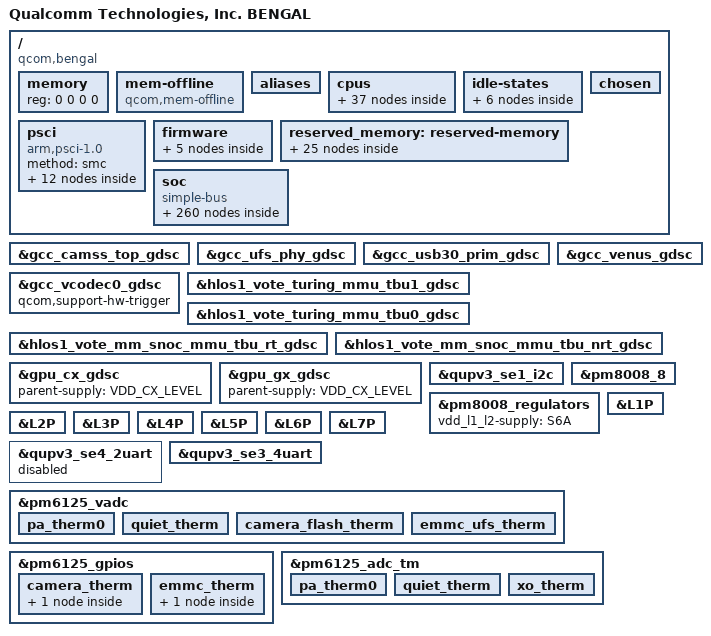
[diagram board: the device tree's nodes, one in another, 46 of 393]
#include <dt-bindings/interrupt-controller/arm-gic.h>
#include <dt-bindings/clock/qcom,rpmcc.h>
#include <dt-bindings/clock/qcom,sm6115-dispcc.h>
#include <dt-bindings/clock/qcom,gcc-sm6115.h>
#include <dt-bindings/clock/qcom,sm6115-gpucc.h>
#include <dt-bindings/spmi/spmi.h>
#include <dt-bindings/interconnect/qcom,bengal.h>
#include <dt-bindings/regulator/qcom,rpmh-regulator-levels.h>

/ {
	model = "Qualcomm Technologies, Inc. BENGAL";
	compatible = "qcom,bengal";
	qcom,msm-id = <417 0x10000>, <444 0x10000>;
	interrupt-parent = <&intc>;

	#address-cells = <2>;
	#size-cells = <2>;
	memory { device_type = "memory"; reg = <0 0 0 0>; };

	mem-offline {
		compatible = "qcom,mem-offline";
		offline-sizes = <0x1 0x40000000 0x0 0x40000000>,
				<0x1 0xc0000000 0x0 0x80000000>,
				<0x2 0xc0000000 0x1 0x40000000>;
		granule = <512>;
	};

	aliases: aliases {
		mmc0 = &sdhc_1; /* SDC1 eMMC slot */
		mmc1 = &sdhc_2; /* SDC2 SD Card slot */
		ufshc1 = &ufshc_mem; /* Embedded UFS slot */
		serial0 = &qupv3_se4_2uart;
		hsuart0 = &qupv3_se3_4uart;
	};

	cpus {
		#address-cells = <2>;
		#size-cells = <0>;

		CPU0: cpu@0 {
			device_type = "cpu";
			compatible = "arm,armv8";
			reg = <0x0 0x0>;
			capacity-dmips-mhz = <1024>;
			dynamic-power-coefficient = <100>;
			cpu-idle-states = <&SILVER_OFF>;
			power-domains = <&CPU_PD0>;
			power-domain-names = "psci";
			enable-method = "psci";
			next-level-cache = <&L2_0>;
			qcom,freq-domain = <&cpufreq_hw 0 7>;
			qcom,lmh-dcvs = <&lmh_dcvs0>;
			#cooling-cells = <2>;
			L2_0: l2-cache {
				compatible = "arm,arch-cache";
				cache-level = <2>;
			};

			L1_I_0: l1-icache {
				compatible = "arm,arch-cache";
			};

			L1_D_0: l1-dcache {
				compatible = "arm,arch-cache";
			};
		};

		CPU1: cpu@1 {
			device_type = "cpu";
			compatible = "arm,armv8";
			reg = <0x0 0x1>;
			capacity-dmips-mhz = <1024>;
			dynamic-power-coefficient = <100>;
			cpu-idle-states = <&SILVER_OFF>;
			power-domains = <&CPU_PD0>;
			power-domain-names = "psci";
			enable-method = "psci";
			next-level-cache = <&L2_0>;
			qcom,freq-domain = <&cpufreq_hw 0 7>;
			qcom,lmh-dcvs = <&lmh_dcvs0>;
			#cooling-cells = <2>;

			L1_I_1: l1-icache {
				compatible = "arm,arch-cache";
			};

			L1_D_1: l1-dcache {
				compatible = "arm,arch-cache";
			};
		};

		CPU2: cpu@2 {
			device_type = "cpu";
			compatible = "arm,armv8";
			reg = <0x0 0x2>;
			capacity-dmips-mhz = <1024>;
			dynamic-power-coefficient = <100>;
			cpu-idle-states = <&SILVER_OFF>;
			power-domains = <&CPU_PD0>;
			power-domain-names = "psci";
			enable-method = "psci";
			next-level-cache = <&L2_0>;
			qcom,freq-domain = <&cpufreq_hw 0 7>;
			qcom,lmh-dcvs = <&lmh_dcvs0>;
			#cooling-cells = <2>;

			L1_I_2: l1-icache {
				compatible = "arm,arch-cache";
			};

			L1_D_2: l1-dcache {
				compatible = "arm,arch-cache";
			};
		};

		CPU3: cpu@3 {
			device_type = "cpu";
			compatible = "arm,armv8";
			reg = <0x0 0x3>;
			capacity-dmips-mhz = <1024>;
			dynamic-power-coefficient = <100>;
			cpu-idle-states = <&SILVER_OFF>;
			power-domains = <&CPU_PD0>;
			power-domain-names = "psci";
			enable-method = "psci";
			next-level-cache = <&L2_0>;
			qcom,freq-domain = <&cpufreq_hw 0 7>;
			qcom,lmh-dcvs = <&lmh_dcvs0>;
			#cooling-cells = <2>;

			L1_I_3: l1-icache {
				compatible = "arm,arch-cache";
			};

			L1_D_3: l1-dcache {
				compatible = "arm,arch-cache";
			};
		};

		CPU4: cpu@100 {
			device_type = "cpu";
			compatible = "arm,armv8";
			reg = <0x0 0x100>;
			cpu-idle-states = <&GOLD_OFF>;
			power-domains = <&CPU_PD4>;
			power-domain-names = "psci";
			enable-method = "psci";
			capacity-dmips-mhz = <1638>;
			dynamic-power-coefficient = <282>;
			next-level-cache = <&L2_1>;
			qcom,freq-domain = <&cpufreq_hw 1 7>;
			qcom,lmh-dcvs = <&lmh_dcvs1>;
			#cooling-cells = <2>;
			L2_1: l2-cache {
				compatible = "arm,arch-cache";
				cache-level = <2>;
			};

			L1_I_100: l1-icache {
				compatible = "arm,arch-cache";
			};

			L1_D_100: l1-dcache {
				compatible = "arm,arch-cache";
			};
		};

		CPU5: cpu@101 {
			device_type = "cpu";
			compatible = "arm,armv8";
			reg = <0x0 0x101>;
			capacity-dmips-mhz = <1638>;
			dynamic-power-coefficient = <282>;
			cpu-idle-states = <&GOLD_OFF>;
			power-domains = <&CPU_PD4>;
			power-domain-names = "psci";
			enable-method = "psci";
			next-level-cache = <&L2_1>;
			qcom,freq-domain = <&cpufreq_hw 1 7>;
			qcom,lmh-dcvs = <&lmh_dcvs1>;
			#cooling-cells = <2>;

			L1_I_101: l1-icache {
				compatible = "arm,arch-cache";
			};

			L1_D_101: l1-dcache {
				compatible = "arm,arch-cache";
			};
		};

		CPU6: cpu@102 {
			device_type = "cpu";
			compatible = "arm,armv8";
			reg = <0x0 0x102>;
			capacity-dmips-mhz = <1638>;
			dynamic-power-coefficient = <282>;
			cpu-idle-states = <&GOLD_OFF>;
			power-domains = <&CPU_PD4>;
			power-domain-names = "psci";
			enable-method = "psci";
			next-level-cache = <&L2_1>;
			qcom,freq-domain = <&cpufreq_hw 1 7>;
			qcom,lmh-dcvs = <&lmh_dcvs1>;
			#cooling-cells = <2>;

			L1_I_102: l1-icache {
				compatible = "arm,arch-cache";
			};

			L1_D_102: l1-dcache {
				compatible = "arm,arch-cache";
			};
		};

		CPU7: cpu@103 {
			device_type = "cpu";
			compatible = "arm,armv8";
			reg = <0x0 0x103>;
			capacity-dmips-mhz = <1638>;
			dynamic-power-coefficient = <282>;
			cpu-idle-states = <&GOLD_OFF>;
			power-domains = <&CPU_PD4>;
			power-domain-names = "psci";
			enable-method = "psci";
			next-level-cache = <&L2_1>;
			qcom,freq-domain = <&cpufreq_hw 1 7>;
			qcom,lmh-dcvs = <&lmh_dcvs1>;
			#cooling-cells = <2>;

			L1_I_103: l1-icache {
				compatible = "arm,arch-cache";
			};

			L1_D_103: l1-dcache {
				compatible = "arm,arch-cache";
			};
		};

		cpu-map {
			cluster0 {
				core0 {
					cpu = <&CPU0>;
				};

				core1 {
					cpu = <&CPU1>;
				};

				core2 {
					cpu = <&CPU2>;
				};

				core3 {
					cpu = <&CPU3>;
				};
			};

			cluster1 {
				core0 {
					cpu = <&CPU4>;
				};

				core1 {
					cpu = <&CPU5>;
				};

				core2 {
					cpu = <&CPU6>;
				};

				core3 {
					cpu = <&CPU7>;
				};
			};
		};
	};

	idle-states {
		SILVER_OFF: silver-c3 {  /* C3 */
			compatible = "arm,idle-state";
			idle-state-name = "pc";
			entry-latency-us = <297>;
			exit-latency-us = <324>;
			min-residency-us = <1110>;
			arm,psci-suspend-param = <0x40000003>;
			local-timer-stop;
		};

		GOLD_OFF: gold-c3 {  /* C3 */
			compatible = "arm,idle-state";
			idle-state-name = "pc";
			entry-latency-us = <290>;
			exit-latency-us = <376>;
			min-residency-us = <1182>;
			arm,psci-suspend-param = <0x40000003>;
			local-timer-stop;
		};

		SILVER_CLUSTER_D3: silver-cluster-d3 { /* D3 */
			compatible = "domain-idle-state";
			idle-state-name = "pwr-l2-pc";
			entry-latency-us = <640>;
			exit-latency-us = <1664>;
			min-residency-us = <8094>;
			arm,psci-suspend-param = <0x41000043>;
		};

		GOLD_CLUSTER_D3: gold-cluster-d3 { /* D3 */
			compatible = "domain-idle-state";
			idle-state-name = "perf-l2-pc";
			entry-latency-us = <800>;
			exit-latency-us = <2118>;
			min-residency-us = <7376>;
			arm,psci-suspend-param = <0x41000043>;
		};

		APSS_WFI: cluster-e1 { /* E1 */
			compatible = "domain-idle-state";
			idle-state-name = "cci-ret";
			entry-latency-us = <108>;
			exit-latency-us = <450>;
			min-residency-us = <153>;
			arm,psci-suspend-param = <0x42000043>;
		};

		APSS_OFF: cluster-e3 { /* E3 */
			compatible = "domain-idle-state";
			idle-state-name = "cci-pc";
			entry-latency-us = <10831>;
			exit-latency-us = <4506>;
			min-residency-us = <15338>;
			arm,psci-suspend-param = <0x42000343>;
		};
	};

	psci {
		compatible = "arm,psci-1.0";
		method = "smc";

		CPU_PD0: cpu-pd0 {
			#power-domain-cells = <0>;
			power-domains = <&CLUSTER_PD0>;
		};

		CPU_PD1: cpu-pd1 {
			#power-domain-cells = <0>;
			power-domains = <&CLUSTER_PD0>;
		};

		CPU_PD2: cpu-pd2 {
			#power-domain-cells = <0>;
			power-domains = <&CLUSTER_PD0>;
		};

		CPU_PD3: cpu-pd3 {
			#power-domain-cells = <0>;
			power-domains = <&CLUSTER_PD0>;
		};

		CPU_PD4: cpu-pd4 {
			#power-domain-cells = <0>;
			power-domains = <&CLUSTER_PD1>;
		};

		CPU_PD5: cpu-pd5 {
			#power-domain-cells = <0>;
			power-domains = <&CLUSTER_PD1>;
		};

		CPU_PD6: cpu-pd6 {
			#power-domain-cells = <0>;
			power-domains = <&CLUSTER_PD1>;
		};

		CPU_PD7: cpu-pd7 {
			#power-domain-cells = <0>;
			power-domains = <&CLUSTER_PD1>;
		};

		CLUSTER_PD0: cluster-pd0 {
			#power-domain-cells = <0>;
			power-domains = <&CLUSTER_PD2>;
			domain-idle-states = <&SILVER_CLUSTER_D3>;
		};

		CLUSTER_PD1: cluster-pd1 {
			#power-domain-cells = <0>;
			power-domains = <&CLUSTER_PD2>;
			domain-idle-states = <&GOLD_CLUSTER_D3>;
		};

		CLUSTER_PD2: cluster-pd2 {
			#power-domain-cells = <0>;
			power-domains = <&CLUSTER_PD3>;
			domain-idle-states = <&APSS_WFI>;
		};

		CLUSTER_PD3: cluster-pd3 {
			#power-domain-cells = <0>;
			domain-idle-states = <&APSS_OFF>;
		};
	};

	firmware: firmware {
		qcom_scm {
			compatible = "qcom,scm";
			qcom,dload-mode = <&tcsr 0x13000>;
		};

		android {
			compatible = "android,firmware";
			vbmeta {
				compatible="android,vbmeta";
				parts = "vbmeta,boot,system,vendor,dtbo,recovery";
			};

			fstab {
				compatible = "android,fstab";
				vendor {
					compatible = "android,vendor";
					dev = "/dev/block/platform/soc/4744000.sdhci/by-name/vendor";
					type = "ext4";
					mnt_flags = "ro,barrier=1,discard";
					fsmgr_flags = "wait,slotselect,avb";
					status = "ok";
				};
			};
		};
	};

	reserved_memory: reserved-memory {
		#address-cells = <2>;
		#size-cells = <2>;
		ranges;

		hyp_mem: hyp_region@45700000 {
			no-map;
			reg = <0x0 0x45700000 0x0 0x600000>;
		};

		xbl_aop_mem: xbl_aop_region@45e00000 {
			no-map;
			reg = <0x0 0x45e00000 0x0 0x140000>;
		};

		sec_apps_mem: sec_apps_region@45fff000 {
			no-map;
			reg = <0x0 0x45fff000 0x0 0x1000>;
		};

		smem_mem: smem_region@46000000 {
			no-map;
			reg = <0x0 0x46000000 0x0 0x200000>;
		};

		removed_mem: removed_region@60000000 {
			no-map;
			reg = <0x0 0x60000000 0x0 0x3900000>;
		};

		pil_modem_mem: modem_region@4ab00000 {
			no-map;
			reg = <0x0 0x4ab00000 0x0 0x6900000>;
		};

		wlan_msa_mem: wlan_msa_region@51900000 {
			no-map;
			reg = <0x0 0x51900000 0x0 0x100000>;
		};

		pil_cdsp_mem: cdsp_regions@51a00000 {
			no-map;
			reg = <0x0 0x51a00000 0x0 0x1e00000>;
		};

		pil_adsp_mem: pil_adsp_region@53800000 {
			no-map;
			reg = <0x0 0x53800000 0x0 0x1e00000>;
		};

		pil_ipa_fw_mem: ipa_fw_region@55600000 {
			no-map;
			reg = <0x0 0x55600000 0x0 0x10000>;
		};

		pil_ipa_gsi_mem: ipa_gsi_region@55610000 {
			no-map;
			reg = <0x0 0x55610000 0x0 0x5000>;
		};

		pil_gpu_mem: gpu_region@55615000 {
			no-map;
			reg = <0x0 0x55615000 0x0 0x2000>;
		};

		video_mem: video_region@55617000 {
			no-map;
			reg = <0x0 0x55617000 0x0 0x700000>;
		};

		user_contig_mem: user_contig_region {
			compatible = "shared-dma-pool";
			alloc-ranges = <0x0 0x00000000 0x0 0xffffffff>;
			reusable;
			alignment = <0x0 0x400000>;
			size = <0x0 0x1000000>;
		};

		non_secure_display_memory: non_secure_display_region {
			compatible = "shared-dma-pool";
			reusable;
			alloc-ranges = <0x0 0x00000000 0x0 0xffffffff>;
			size = <0x0 0xa400000>;
			alignment = <0x0 0x400000>;
		};

		qseecom_mem: qseecom_region {
			compatible = "shared-dma-pool";
			alloc-ranges = <0x0 0x00000000 0x0 0xffffffff>;
			reusable;
			alignment = <0x0 0x400000>;
			size = <0x0 0x1400000>;
		};

		qseecom_ta_mem: qseecom_ta_region {
			compatible = "shared-dma-pool";
			alloc-ranges = <0x0 0x00000000 0x0 0xffffffff>;
			reusable;
			alignment = <0x0 0x400000>;
			size = <0x0 0x1000000>;
		};

		cdsp_sec_mem: cdsp_sec_regions@46200000 {
			no-map;
			reg = <0x0 0x46200000 0x0 0x1e00000>;
		};

		secure_display_memory: secure_display_region {
			compatible = "shared-dma-pool";
			alloc-ranges = <0 0x00000000 0 0xffffffff>;
			reusable;
			alignment = <0 0x400000>;
			size = <0 0x5c00000>;
		};

		adsp_mem: adsp_region {
			compatible = "shared-dma-pool";
			alloc-ranges = <0 0x00000000 0 0xffffffff>;
			reusable;
			alignment = <0 0x400000>;
			size = <0 0x800000>;
		};

		dump_mem: mem_dump_region {
			compatible = "shared-dma-pool";
			alloc-ranges = <0x0 0x00000000 0x0 0xffffffff>;
			reusable;
			size = <0 0x800000>;
		};

		ramoops_mem: ramoops_region {
			compatible = "ramoops";
			alloc-ranges = <0x0 0x00000000 0xffffffff 0xffffffff>;
			size = <0x0 0x200000>;
			pmsg-size = <0x200000>;
			mem-type = <2>;
		};

		audio_cma_mem: audio_cma_region {
			compatible = "shared-dma-pool";
			alloc-ranges = <0x0 0x00000000 0x0 0xffffffff>;
			reusable;
			alignment = <0x0 0x400000>;
			size = <0x0 0x1C00000>;
		};

		/* global autoconfigured region for contiguous allocations */
		system_cma: linux,cma {
			compatible = "shared-dma-pool";
			alloc-ranges = <0x0 0x00000000 0x0 0xffffffff>;
			reusable;
			alignment = <0x0 0x400000>;
			size = <0x0 0x2000000>;
			linux,cma-default;
		};

		va_md_mem: va_md_mem_region {
			compatible = "shared-dma-pool";
			alloc-ranges = <0x0 0x00000000 0x0 0xffffffff>;
			reusable;
			size = <0x0 0x1000000>;
		};

	};

	chosen {
		bootargs = "lpm_levels.sleep_disabled=1 console=ttyMSM0,115200n8 msm_rtb.filter=0x237 service_locator.enable=1 swiotlb=2048 loop.max_part=7 cpufreq.default_governor=performance rcupdate.rcu_expedited=1 rcu_nocbs=0-7 kpti=off export_pmu_events movable_node ftrace_dump_on_oops ssbd=force-off disable_dma32=on cgroup.memory=nokmem,nosocket panic=5";
	};

	soc: soc { };
};

&soc {
	#address-cells = <1>;
	#size-cells = <1>;
	ranges = <0 0 0 0xffffffff>;
	compatible = "simple-bus";

	clk_virt: interconnect {
		compatible = "qcom,bengal-clk_virt";
		qcom,keepalive;
		#interconnect-cells = <1>;
		clock-names = "bus", "bus_a";
		clocks = <&rpmcc RPM_SMD_QUP_CLK>,
		<&rpmcc RPM_SMD_QUP_A_CLK>;
	};

	mmnrt_virt: interconnect@0 {
		compatible = "qcom,bengal-mmnrt_virt";
		#interconnect-cells = <1>;
		qcom,util-factor = <142>;
		qcom,keepalive;
		clock-names = "bus", "bus_a";
		clocks = <&rpmcc RPM_SMD_MMNRT_CLK>,
			 <&rpmcc RPM_SMD_MMNRT_A_CLK>;
	 };

	mmrt_virt: interconnect@1 {
		compatible = "qcom,bengal-mmrt_virt";
		#interconnect-cells = <1>;
		qcom,util-factor = <139>;
		qcom,keepalive;
		clock-names = "bus", "bus_a";
		clocks = <&rpmcc RPM_SMD_MMRT_CLK>,
			 <&rpmcc RPM_SMD_MMRT_A_CLK>;
	 };

	system_noc: interconnect@1880000 {
		compatible = "qcom,bengal-system_noc";
		reg = <0x01880000 0x5f080>;
		#interconnect-cells = <1>;
		qcom,keepalive;
		clock-names = "bus", "bus_a";
		clocks = <&rpmcc RPM_SMD_SNOC_CLK>,
			 <&rpmcc RPM_SMD_SNOC_A_CLK>,
			 <&gcc GCC_CFG_NOC_USB3_PRIM_AXI_CLK>,
			 <&gcc GCC_SYS_NOC_USB3_PRIM_AXI_CLK>;
	};

	config_noc: interconnect@1900000 {
		compatible = "qcom,bengal-config_noc";
		reg = <0x01900000 0x6200>;
		#interconnect-cells = <1>;
		qcom,keepalive;
		clock-names = "bus", "bus_a";
		clocks = <&rpmcc RPM_SMD_CNOC_CLK>,
			 <&rpmcc RPM_SMD_CNOC_A_CLK>;
	 };

	bimc: interconnect@4480000 {
		compatible = "qcom,bengal-bimc";
		reg = <0x04480000 0x80000>;
		#interconnect-cells = <1>;
		qcom,util-factor = <153>;
		qcom,keepalive;
		clock-names = "bus", "bus_a";
		clocks = <&rpmcc RPM_SMD_BIMC_CLK>,
			 <&rpmcc RPM_SMD_BIMC_A_CLK>;
	 };

	intc: interrupt-controller@f200000 {
		compatible = "arm,gic-v3";
		#interrupt-cells = <3>;
		interrupt-controller;
		interrupt-parent = <&intc>;
		#redistributor-regions = <1>;
		redistributor-stride = <0x0 0x20000>;
		reg = <0xf200000 0x10000>,     /* GICD */
		      <0xf300000 0x100000>;    /* GICR * 8 */
		interrupts = <1 9 4>;
	};

	jtag_mm0: jtagmm@9040000 {
		compatible = "qcom,jtagv8-mm";
		reg = <0x9040000 0x1000>;
		reg-names = "etm-base";

		clocks = <&rpmcc RPM_SMD_QDSS_CLK>;
		clock-names = "core_clk";

		qcom,coresight-jtagmm-cpu = <&CPU0>;
	};

	jtag_mm1: jtagmm@9140000 {
		compatible = "qcom,jtagv8-mm";
		reg = <0x9140000 0x1000>;
		reg-names = "etm-base";

		clocks = <&rpmcc RPM_SMD_QDSS_CLK>;
		clock-names = "core_clk";

		qcom,coresight-jtagmm-cpu = <&CPU1>;
	};

	jtag_mm2: jtagmm@9240000 {
		compatible = "qcom,jtagv8-mm";
		reg = <0x9240000 0x1000>;
		reg-names = "etm-base";

		clocks = <&rpmcc RPM_SMD_QDSS_CLK>;
		clock-names = "core_clk";

		qcom,coresight-jtagmm-cpu = <&CPU2>;
	};

	jtag_mm3: jtagmm@9340000 {
		compatible = "qcom,jtagv8-mm";
		reg = <0x9340000 0x1000>;
		reg-names = "etm-base";

		clocks = <&rpmcc RPM_SMD_QDSS_CLK>;
		clock-names = "core_clk";

		qcom,coresight-jtagmm-cpu = <&CPU3>;
	};

	jtag_mm4: jtagmm@9440000 {
		compatible = "qcom,jtagv8-mm";
		reg = <0x9440000 0x1000>;
		reg-names = "etm-base";

		clocks = <&rpmcc RPM_SMD_QDSS_CLK>;
		clock-names = "core_clk";

		qcom,coresight-jtagmm-cpu = <&CPU4>;
	};

	jtag_mm5: jtagmm@9540000 {
		compatible = "qcom,jtagv8-mm";
		reg = <0x9540000 0x1000>;
		reg-names = "etm-base";

		clocks = <&rpmcc RPM_SMD_QDSS_CLK>;
		clock-names = "core_clk";

		qcom,coresight-jtagmm-cpu = <&CPU5>;
	};

	jtag_mm6: jtagmm@9640000 {
		compatible = "qcom,jtagv8-mm";
		reg = <0x9640000 0x1000>;
		reg-names = "etm-base";

		clocks = <&rpmcc RPM_SMD_QDSS_CLK>;
		clock-names = "core_clk";

		qcom,coresight-jtagmm-cpu = <&CPU6>;
	};

	jtag_mm7: jtagmm@9740000 {
		compatible = "qcom,jtagv8-mm";
		reg = <0x9740000 0x1000>;
		reg-names = "etm-base";

		clocks = <&rpmcc RPM_SMD_QDSS_CLK>;
		clock-names = "core_clk";

		qcom,coresight-jtagmm-cpu = <&CPU7>;
	};

	qcom,memshare {
		compatible = "qcom,memshare";

		qcom,client_1 {
			compatible = "qcom,memshare-peripheral";
			qcom,peripheral-size = <0x0>;
			qcom,client-id = <0>;
			qcom,allocate-boot-time;
			label = "modem";
		};

		qcom,client_2 {
			compatible = "qcom,memshare-peripheral";
			qcom,peripheral-size = <0x0>;
			qcom,client-id = <2>;
			label = "modem";
		};

		mem_client_3_size: qcom,client_3 {
			compatible = "qcom,memshare-peripheral";
			qcom,peripheral-size = <0x500000>;
			qcom,client-id = <1>;
			qcom,allocate-on-request;
			label = "modem";
		};
	};

	slimbam: bamdma@0xa580000 {
		compatible = "qcom,bam-v1.7.0";
		qcom,controlled-remotely;
		reg = <0xa584000 0x20000>, <0xa66f000 0x1000>;
		reg-names = "bam", "bam_remote_mem";
		num-channels  = <31>;
		interrupts = <0 284 IRQ_TYPE_LEVEL_HIGH>;
		#dma-cells = <1>;
		qcom,ee = <1>;
		qcom,num-ees = <2>;
	};


	slim_msm: slim@a5c0000 {
		compatible = "qcom,slim-ngd-v1.5.0";
		reg = <0xa5c0000 0x2c000>, <0xa66e000 0x1000>;
		reg-names = "ctrl", "slimbus_remote_mem";
		interrupts = <0 283 IRQ_TYPE_LEVEL_HIGH>;
		dmas = <&slimbam 3>, <&slimbam 4>;
		dma-names = "rx", "tx";
		#address-cells = <1>;
		#size-cells = <0>;
		status = "disabled";
	};


	mpm: interrupt-controller@45f01b8 {
		compatible = "qcom,mpm-bengal", "qcom,mpm";
		reg = <0x45f01b8 0x1000>,
		      <0xf111008 0x4>,  /* MSM_APCS_GCC_BASE 4K */
		      <0xf121000 0x1000>;
		reg-names = "vmpm", "ipc", "timer";
		interrupts = <GIC_SPI 197 IRQ_TYPE_EDGE_RISING>;
		qcom,num-mpm-irqs = <96>;
		interrupt-controller;
		interrupt-parent = <&intc>;
		#interrupt-cells = <2>;
	};

	rpm-sleep-stats@4690000 {
		compatible = "qcom,rpm-sleep-stats";
		reg = <0x04690000 0x400>;
	};

	qcom,rpm-master-stats@45f0150 {
		compatible = "qcom,rpm-master-stats";
		reg = <0x45f0150 0x5000>;
		qcom,masters = "APSS", "MPSS", "ADSP", "CDSP", "TZ";
		qcom,master-stats-version = <2>;
		qcom,master-offset = <4096>;
	};

	cluster-device0 {
		compatible = "qcom,lpm-cluster-dev";
		power-domains = <&CLUSTER_PD0>;
	};

	cluster-device1 {
		compatible = "qcom,lpm-cluster-dev";
		power-domains = <&CLUSTER_PD1>;
	};

	cluster-device2 {
		compatible = "qcom,lpm-cluster-dev";
		power-domains = <&CLUSTER_PD2>;
	};

	cluster-device3 {
		compatible = "qcom,lpm-cluster-dev";
		power-domains = <&CLUSTER_PD3>;
	};

	bluetooth: bt_wcn3990 {
		compatible = "qca,wcn3990";
		qca,bt-sw-ctrl-gpio = <&tlmm 87 0>; /* SW_CTRL */
		qca,bt-vdd-io-supply =   <&L9A>;  /* IO */
		qca,bt-vdd-core-supply = <&L17A>; /* RFA */
		qca,bt-vdd-pa-supply =   <&L23A>; /* CH0 */
		qca,bt-vdd-xtal-supply = <&L16A>; /* XO */

		qca,bt-vdd-io-voltage-level = <1700000 1900000>;
		qca,bt-vdd-core-voltage-level = <1304000 1304000>;
		qca,bt-vdd-pa-voltage-level = <3000000 3312000>;
		qca,bt-vdd-xtal-voltage-level = <1700000 1900000>;

		qca,bt-vdd-io-current-level = <1>; /* LPM/PFM */
		qca,bt-vdd-core-current-level = <1>; /* LPM/PFM */
		qca,bt-vdd-pa-current-level = <1>; /* LPM/PFM */
		qca,bt-vdd-xtal-current-level = <1>; /* LPM/PFM */
	};

	timer {
		compatible = "arm,armv8-timer";
		interrupts = <1 1 0xf08>,
			     <1 2 0xf08>,
			     <1 3 0xf08>,
			     <1 0 0xf08>;
		clock-frequency = <19200000>;
		qcom,erratum-858921;
	};

	dcc: dcc_v2@1be2000 {
		compatible = "qcom,dcc-v2";
		reg = <0x1be2000 0x1000>,
			<0x1bee000 0x2000>;
		reg-names = "dcc-base", "dcc-ram-base";
		dcc-ram-offset = <0x2000>;
	};

	timer@f120000 {
		#address-cells = <1>;
		#size-cells = <1>;
		ranges;
		compatible = "arm,armv7-timer-mem";
		reg = <0xf120000 0x1000>;
		clock-frequency = <19200000>;

		frame@f121000 {
			frame-number = <0>;
			interrupts = <0 8 0x4>,
				     <0 7 0x4>;
			reg = <0xf121000 0x1000>,
			      <0xf122000 0x1000>;
		};

		frame@f123000 {
			frame-number = <1>;
			interrupts = <0 9 0x4>;
			reg = <0xf123000 0x1000>;
			status = "disabled";
		};

		frame@f124000 {
			frame-number = <2>;
			interrupts = <0 10 0x4>;
			reg = <0xf124000 0x1000>;
			status = "disabled";
		};

		frame@f125000 {
			frame-number = <3>;
			interrupts = <0 11 0x4>;
			reg = <0xf125000 0x1000>;
			status = "disabled";
		};

		frame@f126000 {
			frame-number = <4>;
			interrupts = <0 12 0x4>;
			reg = <0xf126000 0x1000>;
			status = "disabled";
		};

		frame@f127000 {
			frame-number = <5>;
			interrupts = <0 13 0x4>;
			reg = <0xf127000 0x1000>;
			status = "disabled";
		};

		frame@f128000 {
			frame-number = <6>;
			interrupts = <0 14 0x4>;
			reg = <0xf128000 0x1000>;
			status = "disabled";
		};
	};

	arm64_cpu_erp {
		compatible = "arm,arm64-cpu-erp";
		interrupt-names = "pri-dbe-irq",
				  "sec-dbe-irq",
				  "pri-ext-irq",
				  "sec-ext-irq";
		interrupts = <0 43 4>,
			     <0 44 4>,
			     <0 41 4>,
			     <0 42 4>;
		poll-delay-ms = <5000>;
	};

	vendor_hooks: qcom,cpu-vendor-hooks {
		compatible = "qcom,cpu-vendor-hooks";
	};

	qcom,msm-imem@c125000 {
		compatible = "qcom,msm-imem";
		reg = <0xc125000 0x1000>;
		ranges = <0x0 0xc125000 0x1000>;
		#address-cells = <1>;
		#size-cells = <1>;

		mem_dump_table@10 {
			compatible = "qcom,msm-imem-mem_dump_table";
			reg = <0x10 0x8>;
		};

		restart_reason@65c {
			compatible = "qcom,msm-imem-restart_reason";
			reg = <0x65c 0x4>;
		};

		dload_type@1c {
			compatible = "qcom,msm-imem-dload-type";
			reg = <0x1c 0x4>;
		};

		boot_stats@6b0 {
			compatible = "qcom,msm-imem-boot_stats";
			reg = <0x6b0 0x20>;
		};

		kaslr_offset@6d0 {
			compatible = "qcom,msm-imem-kaslr_offset";
			reg = <0x6d0 0xc>;
		};

		pil@94c {
			compatible = "qcom,pil-reloc-info";
			reg = <0x94c 0xc8>;
		};

		diag_dload@c8 {
			compatible = "qcom,msm-imem-diag-dload";
			reg = <0xc8 0xc8>;
		};
	};

	restart@440b000 {
		compatible = "qcom,pshold";
		reg = <0x440b000 0x4>,
		      <0x03d3000 0x4>;
		reg-names = "pshold-base", "tcsr-boot-misc-detect";
	};

	qtee_shmbridge {
		compatible = "qcom,tee-shared-memory-bridge";
		qcom,disable-shmbridge-support;
	};

	qcom_seecom: qseecom@61800000 {
		compatible = "qcom,qseecom";
		reg = <0x61800000 0x2100000>;
		reg-names = "secapp-region";
		memory-region = <&qseecom_mem>;
		qseecom_mem = <&qseecom_mem>;
		qseecom_ta_mem = <&qseecom_ta_mem>;
		qcom,no-user-contig-mem-support;
		qcom,hlos-num-ce-hw-instances = <1>;
		qcom,hlos-ce-hw-instance = <0>;
		qcom,qsee-ce-hw-instance = <0>;
		qcom,disk-encrypt-pipe-pair = <2>;
		qcom,support-fde;
		qcom,fde-key-size;
		qcom,appsbl-qseecom-support;
		qcom,commonlib64-loaded-by-uefi;
		qcom,msm-bus,name = "qseecom-noc";
		qcom,msm-bus,num-cases = <4>;
		qcom,msm-bus,num-paths = <1>;
		clock-names =
			"core_clk_src", "core_clk",
			"iface_clk", "bus_clk";
		clocks =
			<&rpmcc RPM_SMD_CE1_CLK>,
			<&rpmcc RPM_SMD_CE1_CLK>,
			<&rpmcc RPM_SMD_CE1_CLK>,
			<&rpmcc RPM_SMD_CE1_CLK>;
		qcom,ce-opp-freq = <192000000>;
		qcom,qsee-reentrancy-support = <2>;
	};

	qcom_smcinvoke: smcinvoke@61800000 {
		compatible = "qcom,smcinvoke";
		qcom,support-legacy_smc;
		reg = <0x61800000 0x2100000>;
		reg-names = "secapp-region";
	};

	qcom_rng: qrng@1b53000 {
		compatible = "qcom,msm-rng";
		reg = <0x1b53000 0x1000>;
		qcom,msm-rng-iface-clk;
		qcom,no-qrng-config;
		interconnect-names = "data_path";
		interconnects = <&bimc MASTER_AMPSS_M0 &config_noc SLAVE_PRNG>;
		clocks = <&gcc GCC_PRNG_AHB_CLK>;
		clock-names = "km_clk_src";
	};

	qcom_tzlog: tz-log@c125720 {
		compatible = "qcom,tz-log";
		reg = <0xc125720 0x3000>;
		qcom,hyplog-enabled;
		hyplog-address-offset = <0x410>;
		hyplog-size-offset = <0x414>;
	};

	qcom_cedev: qcedev@1b20000 {
		compatible = "qcom,qcedev";
		reg = <0x1b20000 0x20000>,
			<0x1b04000 0x24000>;
		reg-names = "crypto-base","crypto-bam-base";
		interrupts = <GIC_SPI 247 IRQ_TYPE_LEVEL_HIGH>;
		qcom,bam-pipe-pair = <3>;
		qcom,ce-hw-instance = <0>;
		qcom,ce-device = <0>;
		qcom,ce-hw-shared;
		qcom,bam-ee = <0>;
		interconnect-names = "data_path";
		interconnects = <&system_noc MASTER_CRYPTO_CORE0 &bimc SLAVE_EBI_CH0>;
		clock-names =
			"core_clk_src", "core_clk",
			"iface_clk", "bus_clk";
		clocks =
			<&rpmcc RPM_SMD_CE1_CLK>,
			<&rpmcc RPM_SMD_CE1_CLK>,
			<&rpmcc RPM_SMD_CE1_CLK>,
			<&rpmcc RPM_SMD_CE1_CLK>;
		qcom,ce-opp-freq = <192000000>;
		qcom,smmu-s1-enable;
		iommus = <&apps_smmu 0x0086 0x0011>,
			 <&apps_smmu 0x0096 0x0011>;
		qcom,iommu-dma = "atomic";

		qcom_cedev_ns_cb {
			compatible = "qcom,qcedev,context-bank";
			label = "ns_context";
			iommus = <&apps_smmu 0x92 0>,
				<&apps_smmu 0x98 0x1>,
				<&apps_smmu 0x9F 0>;
			qcom,iommu-dma-addr-pool = <0x70000000 0X10000000>;
		};

		qcom_cedev_s_cb {
			compatible = "qcom,qcedev,context-bank";
			label = "secure_context";
			iommus = <&apps_smmu 0x93 0>,
				<&apps_smmu 0x9C 0x1>,
				<&apps_smmu 0x9E 0>;
			qcom,iommu-dma-addr-pool = <0x70000000 0X10000000>;
			qcom,iommu-vmid = <0x9>; /* VMID_CP_BITSTREAM */
			qcom,secure-context-bank;
		};
	};

	qcom_crypto: qcrypto@1b20000 {
		compatible = "qcom,qcrypto";
		reg = <0x1b20000 0x20000>,
			<0x1b04000 0x24000>;
		reg-names = "crypto-base","crypto-bam-base";
		interrupts = <GIC_SPI 247 IRQ_TYPE_LEVEL_HIGH>;
		qcom,bam-pipe-pair = <2>;
		qcom,ce-hw-instance = <0>;
		qcom,ce-device = <0>;
		qcom,bam-ee = <0>;
		qcom,ce-hw-shared;
		qcom,clk-mgmt-sus-res;
		interconnect-names = "data_path";
		interconnects = <&system_noc MASTER_CRYPTO_CORE0 &bimc SLAVE_EBI_CH0>;
		clock-names =
			"core_clk_src", "core_clk",
			"iface_clk", "bus_clk";
		clocks =
			<&rpmcc RPM_SMD_CE1_CLK>,
			<&rpmcc RPM_SMD_CE1_CLK>,
			<&rpmcc RPM_SMD_CE1_CLK>,
			<&rpmcc RPM_SMD_CE1_CLK>;
		qcom,use-sw-aes-cbc-ecb-ctr-algo;
		qcom,use-sw-aes-xts-algo;
		qcom,use-sw-aes-ccm-algo;
		qcom,use-sw-ahash-algo;
		qcom,use-sw-aead-algo;
		qcom,use-sw-hmac-algo;
		qcom,smmu-s1-enable;
		iommus = <&apps_smmu 0x0084 0x0011>,
			<&apps_smmu 0x0094 0x0011>;
		qcom,iommu-dma = "atomic";
	};

	qcom,mpm2-sleep-counter@4403000 {
		compatible = "qcom,mpm2-sleep-counter";
		reg = <0x4403000 0x1000>;
		clock-frequency = <32768>;
	};

	qcom,msm-rtb {
		compatible = "qcom,msm-rtb";
		qcom,rtb-size = <0x100000>;
	};

	cpu_pmu: cpu-pmu {
		compatible = "arm,armv8-pmuv3";
		qcom,irq-is-percpu;
		interrupts = <1 6 4>;
	};

	eud: qcom,msm-eud@1610000 {
		compatible = "qcom,msm-eud";
		interrupt-names = "eud_irq";
		interrupts = <GIC_SPI 189 IRQ_TYPE_LEVEL_HIGH>;
		reg = <0x1610000 0x2000>,
		      <0x1612000 0x1000>,
		      <0x3E5018 0x4>;
		reg-names = "eud_base", "eud_mode_mgr2",
				"eud_tcsr_check_reg";
		qcom,secure-eud-en;
		qcom,eud-tcsr-check-enable;
		qcom,eud-clock-vote-req;
		clocks = <&gcc GCC_AHB2PHY_USB_CLK>;
		clock-names = "eud_ahb2phy_clk";
		status = "ok";
	};

	qcom,msm-gladiator-v2@f100000 {
		compatible = "qcom,msm-gladiator-v2";
		reg = <0xf100000 0xdc00>;
		reg-names = "gladiator_base";
		interrupts = <GIC_SPI 22 IRQ_TYPE_LEVEL_HIGH>;
		clock-names = "atb_clk";
		clocks = <&rpmcc RPM_QDSS_CLK>;
	};

	wdog: qcom,wdt@f017000 {
		compatible = "qcom,msm-watchdog";
		reg = <0xf017000 0x1000>;
		reg-names = "wdt-base";
		interrupts = <GIC_SPI 3 IRQ_TYPE_EDGE_RISING>,
			     <GIC_SPI 4 IRQ_TYPE_LEVEL_HIGH>;
		qcom,bark-time = <11000>;
		qcom,pet-time = <9360>;
		qcom,ipi-ping;
		qcom,wakeup-enable;
	};

	rpm_bus: qcom,rpm-smd {
		compatible = "qcom,rpm-smd";
		rpm-channel-name = "rpm_requests";
		interrupts = <GIC_SPI 194 IRQ_TYPE_EDGE_RISING>;
		power-domains = <&CLUSTER_PD3>;
		rpm-channel-type = <15>; /* SMD_APPS_RPM */
	};

	qcom,chd_silver {
		compatible = "qcom,core-hang-detect";
		label = "silver";
		qcom,threshold-arr = <0x0f1880b0 0x0f1980b0
				      0x0f1a80b0 0x0f1b80b0>;
		qcom,config-arr = <0x0f1880b8 0x0f1980b8
				   0x0f1a80b8 0x0f1b80b8>;
	};

	qcom,chd_gold {
		compatible = "qcom,core-hang-detect";
		label = "gold";
		qcom,threshold-arr = <0x0f0880b0 0x0f0980b0
				      0x0f0a80b0 0x0f0b80b0>;
		qcom,config-arr = <0x0f0880b8 0x0f0980b8
				   0x0f0a80b8 0x0f0b80b8>;
	};

	qcom,ghd {
		compatible = "qcom,gladiator-hang-detect";
		qcom,threshold-arr = <0x0f1d141c 0x0f1d1420
				      0x0f1d1424 0x0f1d1428
				      0x0f1d142c 0x0f1d1430>;
		qcom,config-reg = <0x0f1d1434>;
	};

	adsp_pas:remoteproc-adsp@ab00000 {
		compatible = "qcom,bengal-adsp-pas";
		reg = <0xab00000 0x00100>;

		cx-supply = <&L3A_LEVEL>;
		cx-uV-uA = <RPMH_REGULATOR_LEVEL_TURBO 0>;
		mx-supply = <&L2A_LEVEL>;
		mx-uV-uA = <RPMH_REGULATOR_LEVEL_TURBO 0>;
		reg-names = "cx", "mx";

		clocks = <&rpmcc RPM_SMD_XO_CLK_SRC>;
		clock-names = "xo";

		memory-region = <&pil_adsp_mem>;

		/* Inputs from lpass */
		interrupts-extended = <&intc 0 282 1>,
				      <&adsp_smp2p_in 0 0>,
				      <&adsp_smp2p_in 2 0>,
				      <&adsp_smp2p_in 1 0>,
				      <&adsp_smp2p_in 3 0>;

		interrupt-names = "wdog",
				  "fatal",
				  "handover",
				  "ready",
				  "stop-ack";

		/* Outputs to lpass */
		qcom,smem-states = <&adsp_smp2p_out 0>;
		qcom,smem-state-names = "stop";

		glink_edge: glink-edge {
			qcom,remote-pid = <2>;
			transport = "smem";
			mboxes = <&apcs_glb 8>;
			mbox-names = "adsp_smem";
			interrupts = <GIC_SPI 277 IRQ_TYPE_EDGE_RISING>;

			label = "adsp";
			qcom,glink-label = "lpass";

			qcom,adsp_qrtr {
				qcom,glink-channels = "IPCRTR";
				qcom,intents = <0x800  5
						0x2000 3
						0x4400 2>;
				qcom,no-wake-svc = <0x190>;
			};

			qcom,msm_fastrpc_rpmsg {
				compatible = "qcom,msm-fastrpc-rpmsg";
				qcom,glink-channels = "fastrpcglink-apps-dsp";
				qcom,intents = <0x64 64>;
			};

			qcom,apr_tal_rpmsg {
				qcom,glink-channels = "apr_audio_svc";
				qcom,intents = <0x200 20>;
			};
		};
	};

	cdsp_pas: remoteproc-cdsp@b300000 {
		compatible = "qcom,bengal-cdsp-pas";
		reg = <0xb300000 0x100000>;

		cx-supply = <&VDD_CX_LEVEL>;
		cx-uV-uA = <RPMH_REGULATOR_LEVEL_TURBO 100000>;
		reg-names = "cx";

		clocks = <&rpmcc RPM_SMD_XO_CLK_SRC>;
		clock-names = "xo";

		memory-region = <&pil_cdsp_mem>;

		/* Inputs from turing */
		interrupts-extended = <&intc 0 265 1>,
				      <&cdsp_smp2p_in 0 0>,
				      <&cdsp_smp2p_in 2 0>,
				      <&cdsp_smp2p_in 1 0>,
				      <&cdsp_smp2p_in 3 0>;

		interrupt-names = "wdog",
				  "fatal",
				  "handover",
				  "ready",
				  "stop-ack";

		/* Outputs to turing */
		qcom,smem-states = <&cdsp_smp2p_out 0>;
		qcom,smem-state-names = "stop";

		glink-edge {
			qcom,remote-pid = <5>;
			transport = "smem";
			mboxes = <&apcs_glb 28>;
			mbox-names = "cdsp_smem";
			interrupts = <GIC_SPI 261 IRQ_TYPE_EDGE_RISING>;

			label = "cdsp";
			qcom,glink-label = "cdsp";

			qcom,cdsp_qrtr {
				qcom,glink-channels = "IPCRTR";
				qcom,intents = <0x800  5
						0x2000 3
						0x4400 2>;
			};

			qcom,msm_fastrpc_rpmsg {
				compatible = "qcom,msm-fastrpc-rpmsg";
				qcom,glink-channels = "fastrpcglink-apps-dsp";
				qcom,intents = <0x64 64>;
			};

			qcom,msm_cdsprm_rpmsg {
				compatible = "qcom,msm-cdsprm-rpmsg";
				qcom,glink-channels = "cdsprmglink-apps-dsp";
				qcom,intents = <0x20 12>;

				msm_cdsp_rm: qcom,msm_cdsp_rm {
					compatible = "qcom,msm-cdsp-rm";
					qcom,qos-latency-us = <100>;
					qcom,qos-maxhold-ms = <20>;
				};
			};
		};
	};

	mem_dump {
		compatible = "qcom,mem-dump";
		memory-region = <&dump_mem>;

		c0_context {
			qcom,dump-size = <0x800>;
			qcom,dump-id = <0x0>;
		};

		c1_context {
			qcom,dump-size = <0x800>;
			qcom,dump-id = <0x1>;
		};

		c2_context {
			qcom,dump-size = <0x800>;
			qcom,dump-id = <0x2>;
		};

		c3_context {
			qcom,dump-size = <0x800>;
			qcom,dump-id = <0x3>;
		};

		c100_context {
			qcom,dump-size = <0x800>;
			qcom,dump-id = <0x4>;
		};

		c101_context {
			qcom,dump-size = <0x800>;
			qcom,dump-id = <0x5>;
		};

		c102_context {
			qcom,dump-size = <0x800>;
			qcom,dump-id = <0x6>;
		};

		c103_context {
			qcom,dump-size = <0x800>;
			qcom,dump-id = <0x7>;
		};

		c_scandump {
			qcom,dump-size = <0x40000>;
			qcom,dump-id = <0xeb>;
		};

		l1_icache0 {
			qcom,dump-size = <0x9040>;
			qcom,dump-id = <0x60>;
		};

		l1_icache1 {
			qcom,dump-size = <0x9040>;
			qcom,dump-id = <0x61>;
		};

		l1_icache2 {
			qcom,dump-size = <0x9040>;
			qcom,dump-id = <0x62>;
		};

		l1_icache3 {
			qcom,dump-size = <0x9040>;
			qcom,dump-id = <0x63>;
		};

		l1_icache100 {
			qcom,dump-size = <0x12000>;
			qcom,dump-id = <0x64>;
		};

		l1_icache101 {
			qcom,dump-size = <0x12000>;
			qcom,dump-id = <0x65>;
		};

		l1_icache102 {
			qcom,dump-size = <0x12000>;
			qcom,dump-id = <0x66>;
		};

		l1_icache103 {
			qcom,dump-size = <0x12000>;
			qcom,dump-id = <0x67>;
		};

		l1_dcache0 {
			qcom,dump-size = <0x9040>;
			qcom,dump-id = <0x80>;
		};

		l1_dcache1 {
			qcom,dump-size = <0x9040>;
			qcom,dump-id = <0x81>;
		};

		l1_dcache2 {
			qcom,dump-size = <0x9040>;
			qcom,dump-id = <0x82>;
		};

		l1_dcache3 {
			qcom,dump-size = <0x9040>;
			qcom,dump-id = <0x83>;
		};

		l1_dcache100 {
			qcom,dump-size = <0x12000>;
			qcom,dump-id = <0x84>;
		};

		l1_dcache101 {
			qcom,dump-size = <0x12000>;
			qcom,dump-id = <0x85>;
		};

		l1_dcache102 {
			qcom,dump-size = <0x12000>;
			qcom,dump-id = <0x86>;
		};

		l1_dcache103 {
			qcom,dump-size = <0x12000>;
			qcom,dump-id = <0x87>;
		};

		l2_tlb0 {
			qcom,dump-size = <0x2000>;
			qcom,dump-id = <0x120>;
		};

		l2_tlb1 {
			qcom,dump-size = <0x2000>;
			qcom,dump-id = <0x121>;
		};

		l2_tlb2 {
			qcom,dump-size = <0x2000>;
			qcom,dump-id = <0x122>;
		};

		l2_tlb3 {
			qcom,dump-size = <0x2000>;
			qcom,dump-id = <0x123>;
		};

		l2_tlb100 {
			qcom,dump-size = <0x4800>;
			qcom,dump-id = <0x124>;
		};

		l2_tlb101 {
			qcom,dump-size = <0x4800>;
			qcom,dump-id = <0x125>;
		};

		l2_tlb102 {
			qcom,dump-size = <0x4800>;
			qcom,dump-id = <0x126>;
		};

		l2_tlb103 {
			qcom,dump-size = <0x4800>;
			qcom,dump-id = <0x127>;
		};

		rpm_sw {
			qcom,dump-size = <0x28000>;
			qcom,dump-id = <0xea>;
		};

		pmic {
			qcom,dump-size = <0x40000>;
			qcom,dump-id = <0xe4>;
		};

		fcm {
			qcom,dump-size = <0x8400>;
			qcom,dump-id = <0xee>;
		};

		tmc_etf {
			qcom,dump-size = <0x8000>;
			qcom,dump-id = <0xf0>;
		};

		etr_reg {
			qcom,dump-size = <0x1000>;
			qcom,dump-id = <0x100>;
		};

		etf_reg {
			qcom,dump-size = <0x1000>;
			qcom,dump-id = <0x101>;
		};

		misc_data {
			qcom,dump-size = <0x1000>;
			qcom,dump-id = <0xe8>;
		};
	};


	sdhc1_opp_table: sdhc1-opp-table {
		compatible = "operating-points-v2";

		opp-100000000 {
			opp-hz = /bits/ 64 <100000000>;
			opp-peak-kBps = <250000 133320>;
			opp-avg-kBps = <104000 0>;
		};

		opp-384000000 {
			opp-hz = /bits/ 64 <384000000>;
			opp-peak-kBps = <800000 300000>;
			opp-avg-kBps = <400000 0>;
		};
	};

	sdhc_1: sdhci@4744000 {
		status = "disabled";

		compatible = "qcom,sdhci-msm-v5";
		reg = <0x4744000 0x1000>, <0x4745000 0x1000>,
		      <0x4748000 0x8000>;
		reg-names = "hc", "cqhci", "cqhci_ice";

		qcom,iommu-dma-addr-pool = <0x40000000 0x10000000>;
		qcom,iommu-geometry = <0x40000000 0x10000000>;

		interrupts-extended = <&intc GIC_SPI 348 IRQ_TYPE_LEVEL_HIGH>,
				<&intc GIC_SPI 352 IRQ_TYPE_LEVEL_HIGH>,
				<&tlmm 19 IRQ_TYPE_EDGE_RISING>;
		interrupt-names = "hc_irq", "pwr_irq", "tb_trig_irq";

		bus-width = <8>;
		non-removable;
		supports-cqe;

		cap-mmc-hw-reset;

		nvmem-cells = <&boot_config>;
		nvmem-cell-names = "boot_conf";

		no-sd;
		no-sdio;
		qcom,restore-after-cx-collapse;

		mmc-ddr-1_8v;
		mmc-hs200-1_8v;

		mmc-hs400-1_8v;
		mmc-hs400-enhanced-strobe;

		qcom,devfreq,freq-table = <50000000 200000000>;
		qcom,scaling-lower-bus-speed-mode = "DDR52";

		clocks = <&gcc GCC_SDCC1_AHB_CLK>,
			<&gcc GCC_SDCC1_APPS_CLK>,
			<&gcc GCC_SDCC1_ICE_CORE_CLK>;
		clock-names = "iface", "core", "ice_core";

		qcom,ice-clk-rates = <300000000 100000000>;

		interconnects = <&system_noc MASTER_SDCC_1 &bimc SLAVE_EBI_CH0>,
			<&bimc MASTER_AMPSS_M0 &config_noc SLAVE_SDCC_1>;
		interconnect-names = "sdhc-ddr","cpu-sdhc";
		operating-points-v2 = <&sdhc1_opp_table>;

		/* Add support for gcc hw reset */
		resets = <&gcc GCC_SDCC1_BCR>;
		reset-names = "core_reset";

		/* DLL HSR settings. Refer go/hsr - <Target> DLL settings */
		qcom,dll-hsr-list = <0x000f642c 0x0 0x0 0x00010800 0x80040850>;

		iommus = <&apps_smmu 0xC0 0x0>;
		qcom,iommu-dma = "fastmap";

		qos0 {
			mask = <0xf0>;
			vote = <44>;
		};

		qos1 {
			mask = <0x0f>;
			vote = <44>;
		};
	};

	sdhc2_opp_table: sdhc2-opp-table {
		compatible = "operating-points-v2";

		opp-100000000 {
			opp-hz = /bits/ 64 <100000000>;
			opp-peak-kBps = <250000 133320>;
			opp-avg-kBps = <50000 0>;
		};

		opp-202000000 {
			opp-hz = /bits/ 64 <202000000>;
			opp-peak-kBps = <800000 300000>;
			opp-avg-kBps = <104000 0>;
		};
	};

	sdhc_2: sdhci@4784000 {
		status = "disabled";

		compatible = "qcom,sdhci-msm-v5";
		reg = <0x4784000 0x1000>;
		reg-names = "hc";

		qcom,iommu-dma-addr-pool = <0x40000000 0x10000000>;
		qcom,iommu-geometry = <0x40000000 0x10000000>;

		interrupts = <GIC_SPI 350 IRQ_TYPE_LEVEL_HIGH>,
				<GIC_SPI 353 IRQ_TYPE_LEVEL_HIGH>;
		interrupt-names = "hc_irq", "pwr_irq";

		bus-width = <4>;
		no-sdio;

		no-mmc;
		qcom,restore-after-cx-collapse;

		clocks = <&gcc GCC_SDCC2_AHB_CLK>,
			<&gcc GCC_SDCC2_APPS_CLK>;
		clock-names = "iface", "core";

		interconnects = <&system_noc MASTER_SDCC_2 &bimc SLAVE_EBI_CH0>,
			<&bimc MASTER_AMPSS_M0 &config_noc SLAVE_SDCC_2>;
		interconnect-names = "sdhc-ddr","cpu-sdhc";
		operating-points-v2 = <&sdhc2_opp_table>;

		/* DLL HSR settings. Refer go/hsr - <Target> DLL settings */
		qcom,dll-hsr-list = <0x0007642c 0x0 0x0 0x00010800 0x80040868>;

		iommus = <&apps_smmu 0x00A0 0x0>;
		qcom,iommu-dma = "fastmap";

		qos0 {
			mask = <0xf0>;
			vote = <44>;
		};

		qos1 {
			mask = <0x0f>;
			vote = <44>;
		};
	};

	ufsphy_mem: ufsphy_mem@4807000 {
		reg = <0x4807000 0xdb8>; /* PHY regs */
		reg-names = "phy_mem";
		#phy-cells = <0>;

		lanes-per-direction = <1>;

		clock-names = "ref_clk_src",
			"ref_clk",
			"ref_aux_clk";
		clocks = <&rpmcc RPM_SMD_XO_CLK_SRC>,
			<&gcc GCC_UFS_CLKREF_CLK>,
			<&gcc GCC_UFS_PHY_PHY_AUX_CLK>;

		resets = <&ufshc_mem 0>;
		status = "disabled";
	};

	ufshc_mem: ufshc@4804000 {
		compatible = "qcom,ufshc";
		reg = <0x4804000 0x3000>, <0x4810000 0x8000>;
		reg-names = "ufs_mem", "ufs_ice";
		interrupts = <GIC_SPI 356 IRQ_TYPE_LEVEL_HIGH>;
		phys = <&ufsphy_mem>;
		phy-names = "ufsphy";
		#reset-cells = <1>;

		qcom,dynamic-irq-affinity;

		lanes-per-direction = <1>;
		limit-phy-submode = <0>;

		nvmem-cells = <&boot_config>;
		nvmem-cell-names = "boot_conf";

		clock-names =
			"core_clk",
			"bus_aggr_clk",
			"iface_clk",
			"core_clk_unipro",
			"core_clk_ice",
			"ref_clk",
			"tx_lane0_sync_clk",
			"rx_lane0_sync_clk";
		clocks =
			<&gcc GCC_UFS_PHY_AXI_CLK>,
			<&gcc GCC_SYS_NOC_UFS_PHY_AXI_CLK>,
			<&gcc GCC_UFS_PHY_AHB_CLK>,
			<&gcc GCC_UFS_PHY_UNIPRO_CORE_CLK>,
			<&gcc GCC_UFS_PHY_ICE_CORE_CLK>,
			<&rpmcc RPM_SMD_XO_CLK_SRC>,
			<&gcc GCC_UFS_PHY_TX_SYMBOL_0_CLK>,
			<&gcc GCC_UFS_PHY_RX_SYMBOL_0_CLK>;
		freq-table-hz =
			<50000000 200000000>,
			<0 0>,
			<0 0>,
			<37500000 150000000>,
			<75000000 300000000>,
			<0 0>,
			<0 0>,
			<0 0>;

		interconnects = <&system_noc MASTER_UFS_MEM &bimc SLAVE_EBI_CH0>,
			<&bimc MASTER_AMPSS_M0 &config_noc SLAVE_UFS_MEM_CFG>;
		interconnect-names = "ufs-ddr", "cpu-ufs";

		qcom,ufs-bus-bw,name = "ufshc_mem";
		qcom,ufs-bus-bw,num-cases = <12>;
		qcom,ufs-bus-bw,num-paths = <2>;
		qcom,ufs-bus-bw,vectors-KBps =
		/*
		 * During HS G3 UFS runs at nominal voltage corner, vote
		 * higher bandwidth to push other buses in the data path
		 * to run at nominal to achieve max throughput.
		 * 4GBps pushes BIMC to run at nominal.
		 * 200MBps pushes CNOC to run at nominal.
		 * Vote for half of this bandwidth for HS G3 1-lane.
		 * For max bandwidth, vote high enough to push the buses
		 * to run in turbo voltage corner.
		 */
		<123 512 0 0>, <1 757 0 0>,          /* No vote */
		<123 512 922 0>, <1 757 1000 0>,     /* PWM G1 */
		<123 512 1844 0>, <1 757 1000 0>,    /* PWM G2 */
		<123 512 3688 0>, <1 757 1000 0>,    /* PWM G3 */
		<123 512 7376 0>, <1 757 1000 0>,    /* PWM G4 */
		<123 512 127796 0>, <1 757 1000 0>,  /* HS G1 RA */
		<123 512 255591 0>, <1 757 1000 0>,  /* HS G2 RA */
		<123 512 2097152 0>, <1 757 102400 0>,  /* HS G3 RA */
		<123 512 149422 0>, <1 757 1000 0>,  /* HS G1 RB */
		<123 512 298189 0>, <1 757 1000 0>,  /* HS G2 RB */
		<123 512 2097152 0>, <1 757 102400 0>,  /* HS G3 RB */
		<123 512 7643136 0>, <1 757 307200 0>; /* Max. bandwidth */

		qcom,bus-vector-names = "MIN",
		"PWM_G1_L1", "PWM_G2_L1", "PWM_G3_L1", "PWM_G4_L1",
		"HS_RA_G1_L1", "HS_RA_G2_L1", "HS_RA_G3_L1",
		"HS_RB_G1_L1", "HS_RB_G2_L1", "HS_RB_G3_L1",
		"MAX";


		resets = <&gcc GCC_UFS_PHY_BCR>;
		reset-names = "core_reset";
		non-removable;
		iommus = <&apps_smmu 0x100 0x0>;
		qcom,iommu-dma = "fastmap";

		status = "disabled";
		qos0 {
			vote = <44>;
			perf;
		};

		qos1 {
			vote = <44>;
		};
	};

	thermal_zones: thermal-zones {};

	qcom,secure-buffer {
		compatible = "qcom,secure-buffer";
	};

	logbuf: qcom,logbuf-vendor-hooks {
		compatible = "qcom,logbuf-vendor-hooks";
	};

	qcom,mem-buf {
		compatible = "qcom,mem-buf";
		qcom,vmid = <3>;
		qcom,mem-buf-capabilities = "supplier";
	};

	qcom,mem-buf-msgq {
		compatible = "qcom,mem-buf-msgq";
	};

	tsens0:tsens@c222000 {
		compatible = "qcom,tsens24xx";
		reg = <0x04410000  0x8>,
			<0x04411000  0x1ff>;
		reg-names = "tsens_srot_physical",
			"tsens_tm_physical";
		interrupts = <GIC_SPI 275 IRQ_TYPE_LEVEL_HIGH>,
				<GIC_SPI 190 IRQ_TYPE_LEVEL_HIGH>;
		interrupt-names = "tsens-upper-lower", "tsens-critical";
		tsens-reinit-wa;
		#thermal-sensor-cells = <1>;
	};

	clocks {
		xo_board: xo_board {
			compatible = "fixed-clock";
			clock-frequency = <19200000>;
			clock-output-names = "xo_board";
			#clock-cells = <0>;
		};

		sleep_clk: sleep_clk {
			compatible = "fixed-clock";
			clock-frequency = <32764>;
			clock-output-names = "sleep_clk";
			#clock-cells = <0>;
		};
	};

	rpmcc: qcom,rpmcc {
		compatible = "qcom,rpmcc-khaje";
		#clock-cells = <1>;
	};

	qcom,rmtfs_sharedmem@0 {
		compatible = "qcom,sharedmem-uio";
		reg = <0x0 0x300000>;
		reg-names = "rmtfs";
		qcom,client-id = <0x00000001>;
		qcom,guard-memory;
		qcom,vm-nav-path;
	};

	gcc: clock-controller@1400000 {
		compatible = "qcom,gcc-sm6115", "syscon";
		reg = <0x1400000 0x1f0000>;
		reg-names = "cc_base";
		vdd_cx-supply = <&VDD_CX_LEVEL>;
		vdd_cx_ao-supply = <&VDD_CX_LEVEL_AO>;
		vdd_mx-supply = <&VDD_MX_LEVEL>;
		clocks = <&rpmcc RPM_SMD_XO_CLK_SRC>,
			<&rpmcc RPM_SMD_XO_A_CLK_SRC>,
			<&sleep_clk>;
		clock-names = "bi_tcxo",
				"bi_tcxo_ao", "sleep_clk";
		#clock-cells = <1>;
		#reset-cells = <1>;
	};

	dispcc: clock-controller@5f00000 {
		compatible = "qcom,sm6115-dispcc", "syscon";
		reg = <0x05f00000 0x20000>;
		reg-names = "cc_base";
		vdd_cx-supply = <&VDD_CX_LEVEL>;
		clocks = <&rpmcc RPM_SMD_XO_CLK_SRC>,
			<&rpmcc RPM_SMD_XO_A_CLK_SRC>,
			<&sleep_clk>,
			<&gcc GCC_DISP_GPLL0_DIV_CLK_SRC>;
		clock-names = "bi_tcxo", "bi_tcxo_ao",
			      "sleep_clk",
			      "gcc_disp_gpll0_div_clk_src";
		#clock-cells = <1>;
		#reset-cells = <1>;
	};

	gpucc: clock-controller@5990000 {
		compatible = "qcom,sm6115-gpucc", "syscon";
		reg = <0x5990000 0x9000>;
		reg-names = "cc_base";
		vdd_cx-supply = <&VDD_CX_LEVEL>;
		vdd_mx-supply = <&VDD_MX_LEVEL>;
		clocks = <&rpmcc RPM_SMD_XO_CLK_SRC>,
			<&gcc GCC_GPU_GPLL0_CLK_SRC>,
			<&gcc GCC_GPU_GPLL0_DIV_CLK_SRC>;
		clock-names = "bi_tcxo",
				"gcc_gpu_gpll0_clk_src",
				"gcc_gpu_gpll0_div_clk_src";
		#clock-cells = <1>;
		#reset-cells = <1>;
	};

	mccc_debug: syscon@447d200 {
		compatible = "syscon";
		reg = <0x447d200 0x100>;
	};

	cpucc_debug: syscon@f11101c {
		compatible = "syscon";
		reg = <0xf11101c 0x4>;
	};

	debugcc: debug-clock-controller@0 {
		compatible = "qcom,sm6115-debugcc";
		qcom,gcc = <&gcc>;
		qcom,dispcc = <&dispcc>;
		qcom,gpucc = <&gpucc>;
		qcom,mccc = <&mccc_debug>;
		qcom,cpucc = <&cpucc_debug>;
		clocks = <&rpmcc RPM_SMD_XO_CLK_SRC>,
			 <&gcc 0>,
			 <&dispcc 0>,
			 <&gpucc 0>;
		clock-names = "xo_clk_src",
			      "gcc",
			      "dispcc",
			      "gpucc";
		#clock-cells = <1>;
	};

	cpufreq_hw: qcom,cpufreq-hw {
		compatible = "qcom,cpufreq-hw";
		reg = <0xf521000 0x1000>, <0xf523000 0x1000>;
		reg-names = "freq-domain0", "freq-domain1";
		clocks = <&rpmcc RPM_SMD_XO_CLK_SRC>, <&gcc GPLL0>;
		clock-names = "xo", "alternate";
		qcom,no-accumulative-counter;
		qcom,max-lut-entries = <12>;
		#freq-domain-cells = <2>;
	};

	dload_mode {
		compatible = "qcom,dload-mode";
	};

	mini_dump_mode {
		compatible = "qcom,minidump";
		status = "ok";
	};

	va_mini_dump {
		compatible = "qcom,va-minidump";
		memory-region = <&va_md_mem>;
		status = "ok";
	};

	tcsr_mutex_block: syscon@00340000 {
		compatible = "syscon";
		reg = <0x340000 0x20000>;
	};

	tcsr_mutex: hwlock {
		compatible = "qcom,tcsr-mutex";
		syscon = <&tcsr_mutex_block 0 0x1000>;
		#hwlock-cells = <1>;
	};

	smem: qcom,smem {
		compatible = "qcom,smem";
		memory-region = <&smem_mem>;
		hwlocks = <&tcsr_mutex 3>;
	};

	rpm_msg_ram: memory@045f0000 {
			compatible = "qcom,rpm-msg-ram";
			reg = <0x45f0000 0x7000>;
	};

	apcs_glb: mailbox@0f111000 {
		compatible = "qcom,bengal-apcs-hmss-global";
		reg = <0xF111000 0x1000>;

		#mbox-cells = <1>;
	};

	qfprom_sys: qfprom@0 {
		compatible = "qcom,qfprom-sys";

		nvmem-cells = <&adsp_variant>,
				<&feat_conf5>,
				<&feat_conf10>;
		nvmem-cell-names = "adsp_variant",
				"feat_conf5",
				"feat_conf10";
	};

	qcom,msm-cdsp-loader {
		compatible = "qcom,cdsp-loader";
		qcom,proc-img-to-load = "cdsp";
		qcom,rproc-handle = <&cdsp_pas>;
	};

	qcom,msm-adsprpc-mem {
		compatible = "qcom,msm-adsprpc-mem-region";
		memory-region = <&adsp_mem>;
		restrict-access;
	};

	qcom,msm_fastrpc {
		compatible = "qcom,msm-fastrpc-compute";
		qcom,rpc-latency-us = <611>;
		qcom,adsp-remoteheap-vmid = <22 37>;
		qcom,fastrpc-adsp-audio-pdr;
		qcom,fastrpc-adsp-sensors-pdr;

		qcom,msm_fastrpc_compute_cb1 {
			compatible = "qcom,msm-fastrpc-compute-cb";
			label = "cdsprpc-smd";
			iommus = <&apps_smmu 0x0C01 0x0>;
			qcom,iommu-dma-addr-pool = <0x80000000 0x78000000>;
			qcom,iommu-faults = "stall-disable", "HUPCF";
		};

		qcom,msm_fastrpc_compute_cb2 {
			compatible = "qcom,msm-fastrpc-compute-cb";
			label = "cdsprpc-smd";
			iommus = <&apps_smmu 0x0C02 0x0>;
			qcom,iommu-dma-addr-pool = <0x80000000 0x78000000>;
			qcom,iommu-faults = "stall-disable", "HUPCF";
		};

		qcom,msm_fastrpc_compute_cb3 {
			compatible = "qcom,msm-fastrpc-compute-cb";
			label = "cdsprpc-smd";
			iommus = <&apps_smmu 0x0C03 0x0>;
			qcom,iommu-dma-addr-pool = <0x80000000 0x78000000>;
			qcom,iommu-faults = "stall-disable", "HUPCF";
		};

		qcom,msm_fastrpc_compute_cb4 {
			compatible = "qcom,msm-fastrpc-compute-cb";
			label = "cdsprpc-smd";
			iommus = <&apps_smmu 0x0C04 0x0>;
			qcom,iommu-dma-addr-pool = <0x80000000 0x78000000>;
			qcom,iommu-faults = "stall-disable", "HUPCF";
		};

		qcom,msm_fastrpc_compute_cb5 {
			compatible = "qcom,msm-fastrpc-compute-cb";
			label = "cdsprpc-smd";
			iommus = <&apps_smmu 0x0C05 0x0>;
			qcom,iommu-dma-addr-pool = <0x80000000 0x78000000>;
			qcom,iommu-faults = "stall-disable", "HUPCF";
		};

		qcom,msm_fastrpc_compute_cb6 {
			compatible = "qcom,msm-fastrpc-compute-cb";
			label = "cdsprpc-smd";
			iommus = <&apps_smmu 0x0C06 0x0>;
			qcom,iommu-dma-addr-pool = <0x80000000 0x78000000>;
			qcom,iommu-faults = "stall-disable", "HUPCF";
		};

		qcom,msm_fastrpc_compute_cb9 {
			compatible = "qcom,msm-fastrpc-compute-cb";
			label = "cdsprpc-smd";
			qcom,secure-context-bank;
			iommus = <&apps_smmu 0x0C09 0x0>;
			qcom,iommu-dma-addr-pool = <0x80000000 0x78000000>;
			qcom,iommu-faults = "stall-disable", "HUPCF";
		};

		qcom,msm_fastrpc_compute_cb10 {
			compatible = "qcom,msm-fastrpc-compute-cb";
			label = "adsprpc-smd";
			iommus = <&apps_smmu 0x01C3 0x0>;
			qcom,iommu-dma-addr-pool = <0x80000000 0x78000000>;
			qcom,iommu-faults = "stall-disable", "HUPCF";
		};

		qcom,msm_fastrpc_compute_cb11 {
			compatible = "qcom,msm-fastrpc-compute-cb";
			label = "adsprpc-smd";
			iommus = <&apps_smmu 0x01C4 0x0>;
			qcom,iommu-dma-addr-pool = <0x80000000 0x78000000>;
			qcom,iommu-faults = "stall-disable", "HUPCF";
		};

		qcom,msm_fastrpc_compute_cb12 {
			compatible = "qcom,msm-fastrpc-compute-cb";
			label = "adsprpc-smd";
			iommus = <&apps_smmu 0x01C5 0x0>;
			qcom,iommu-dma-addr-pool = <0x80000000 0x78000000>;
			qcom,iommu-faults = "stall-disable", "HUPCF";
		};

		qcom,msm_fastrpc_compute_cb13 {
			compatible = "qcom,msm-fastrpc-compute-cb";
			label = "adsprpc-smd";
			iommus = <&apps_smmu 0x01C6 0x0>;
			qcom,iommu-dma-addr-pool = <0x80000000 0x78000000>;
			qcom,iommu-faults = "stall-disable", "HUPCF";
		};

		qcom,msm_fastrpc_compute_cb14 {
			compatible = "qcom,msm-fastrpc-compute-cb";
			label = "adsprpc-smd";
			iommus = <&apps_smmu 0x01C7 0x0>;
			qcom,iommu-dma-addr-pool = <0x80000000 0x78000000>;
			qcom,iommu-faults = "stall-disable", "HUPCF";
		};

	};

	rpm-glink {
		compatible = "qcom,glink-rpm";
		interrupts = <GIC_SPI 194 IRQ_TYPE_EDGE_RISING>;
		qcom,rpm-msg-ram = <&rpm_msg_ram>;
		mboxes = <&apcs_glb 0>;
	};

	qcom,glinkpkt {
		compatible = "qcom,glinkpkt";

		qcom,glinkpkt-at-mdm0 {
			qcom,glinkpkt-edge = "mpss";
			qcom,glinkpkt-ch-name = "DS";
			qcom,glinkpkt-dev-name = "at_mdm0";
		};

		qcom,glinkpkt-apr-apps2 {
			qcom,glinkpkt-edge = "adsp";
			qcom,glinkpkt-ch-name = "apr_apps2";
			qcom,glinkpkt-dev-name = "apr_apps2";
		};

		qcom,glinkpkt-data40-cntl {
			qcom,glinkpkt-edge = "mpss";
			qcom,glinkpkt-ch-name = "DATA40_CNTL";
			qcom,glinkpkt-dev-name = "smdcntl8";
		};

		qcom,glinkpkt-data1 {
			qcom,glinkpkt-edge = "mpss";
			qcom,glinkpkt-ch-name = "DATA1";
			qcom,glinkpkt-dev-name = "smd7";
		};

		qcom,glinkpkt-data4 {
			qcom,glinkpkt-edge = "mpss";
			qcom,glinkpkt-ch-name = "DATA4";
			qcom,glinkpkt-dev-name = "smd8";
		};

		qcom,glinkpkt-data11 {
			qcom,glinkpkt-edge = "mpss";
			qcom,glinkpkt-ch-name = "DATA11";
			qcom,glinkpkt-dev-name = "smd11";
		};
	};

	qcom,glink {
		compatible = "qcom,glink";
	};

	tcsr: syscon@0x003C0000 {
		compatible = "syscon";
		reg = <0x003C0000 0x40000>;
	};

	qcom,smp2p_sleepstate {
		compatible = "qcom,smp2p-sleepstate";
		qcom,smem-states = <&sleepstate_smp2p_out 0>;
		interrupt-parent = <&sleepstate_smp2p_in>;
		interrupts = <0 0>;
		interrupt-names = "smp2p-sleepstate-in";
	};

	qcom,smp2p-modem {
		compatible = "qcom,smp2p";
		qcom,smem = <435>, <428>;
		interrupts = <GIC_SPI 70 IRQ_TYPE_EDGE_RISING>;
		mboxes = <&apcs_glb 14>;
		qcom,local-pid = <0>;
		qcom,remote-pid = <1>;

		modem_smp2p_out: master-kernel {
			qcom,entry-name = "master-kernel";
			#qcom,smem-state-cells = <1>;
		};

		modem_smp2p_in: slave-kernel {
			qcom,entry-name = "slave-kernel";
			interrupt-controller;
			#interrupt-cells = <2>;
		};

		smp2p_ipa_1_out: qcom,smp2p-ipa-1-out {
			qcom,entry-name = "ipa";
			#qcom,smem-state-cells = <1>;
		};

		/* ipa - inbound entry from mss */
		smp2p_ipa_1_in: qcom,smp2p-ipa-1-in {
			qcom,entry-name = "ipa";
			interrupt-controller;
			#interrupt-cells = <2>;
		};
	};

	qcom,smp2p-adsp {
		compatible = "qcom,smp2p";
		qcom,smem = <443>, <429>;
		interrupts = <GIC_SPI 279 IRQ_TYPE_EDGE_RISING>;
		mboxes = <&apcs_glb 10>;
		qcom,local-pid = <0>;
		qcom,remote-pid = <2>;

		adsp_smp2p_out: master-kernel {
			qcom,entry-name = "master-kernel";
			#qcom,smem-state-cells = <1>;
		};

		adsp_smp2p_in: slave-kernel {
			qcom,entry-name = "slave-kernel";
			interrupt-controller;
			#interrupt-cells = <2>;
		};

		smp2p_rdbg2_out: qcom,smp2p-rdbg2-out {
			qcom,entry-name = "rdbg";
			#qcom,smem-state-cells = <1>;
		};

		smp2p_rdbg2_in: qcom,smp2p-rdbg2-in {
			qcom,entry-name = "rdbg";
			interrupt-controller;
			#interrupt-cells = <2>;
		};

		sleepstate_smp2p_out: sleepstate-out {
			qcom,entry-name = "sleepstate";
			#qcom,smem-state-cells = <1>;
		};

		sleepstate_smp2p_in: qcom,sleepstate-in {
			qcom,entry-name = "sleepstate_see";
			interrupt-controller;
			#interrupt-cells = <2>;
		};
	};

	qcom,smp2p-cdsp {
		compatible = "qcom,smp2p";
		qcom,smem = <94>, <432>;
		interrupts = <GIC_SPI 263 IRQ_TYPE_EDGE_RISING>;
		mboxes = <&apcs_glb 30>;
		qcom,local-pid = <0>;
		qcom,remote-pid = <5>;

		cdsp_smp2p_out: master-kernel {
			qcom,entry-name = "master-kernel";
			#qcom,smem-state-cells = <1>;
		};

		cdsp_smp2p_in: slave-kernel {
			qcom,entry-name = "slave-kernel";
			interrupt-controller;
			#interrupt-cells = <2>;
		};

		smp2p_rdbg5_out: qcom,smp2p-rdbg5-out {
			qcom,entry-name = "rdbg";
			#qcom,smem-state-cells = <1>;
		};

		smp2p_rdbg5_in: qcom,smp2p-rdbg5-in {
			qcom,entry-name = "rdbg";
			interrupt-controller;
			#interrupt-cells = <2>;
		};
	};

	qcom,sps {
		compatible = "qcom,msm-sps-4k";
		qcom,pipe-attr-ee;
	};

	qfprom: qfprom@1b40000 {
		compatible = "qcom,qfprom";
		reg = <0x1b40000 0x7000>;
		#address-cells = <1>;
		#size-cells = <1>;
		read-only;
		ranges;

		stm_debug_fuse: stm@20f0 {
			reg = <0x20f0 0x4>;
		};

		feat_conf5: feat_conf5@6018 {
			reg = <0x6018 0x4>;
		};

		feat_conf10: feat_conf10@602c {
			reg = <0x602c 0x4>;
		};

		adsp_variant: adsp_variant@6011 {
			reg = <0x6011 0x1>;
			bits = <3 1>;
		};

		gpu_speed_bin: gpu_speed_bin@6006 {
			reg = <0x6006 0x2>;
			bits = <5 8>;
		};

		gpu_gaming_bin: gpu_gaming_bin@602d {
			reg = <0x602d 0x1>;
			bits = <5 1>;
		};

		boot_config: boot_config@6070 {
			reg = <0x6070 0x4>;
		};
	};

	spmi_bus: qcom,spmi@1c40000 {
		compatible = "qcom,spmi-pmic-arb";
		reg = <0x1c40000 0x1100>,
			<0x1e00000 0x2000000>,
			<0x3e00000 0x100000>,
			<0x3f00000 0xa0000>,
			<0x1c0a000 0x26000>;
		reg-names = "core", "chnls", "obsrvr", "intr", "cnfg";
		interrupt-names = "periph_irq";
		interrupts-extended = <&mpm 86 IRQ_TYPE_LEVEL_HIGH>;
		qcom,ee = <0>;
		qcom,channel = <0>;
		#address-cells = <1>;
		#size-cells = <1>;
		interrupt-controller;
		#interrupt-cells = <4>;
		cell-index = <0>;
	};

	cx_ipeak_lm: cx_ipeak@3ed000 {
		compatible = "qcom,cx-ipeak-v2";
		reg = <0x3ed000 0xe008>;
	};

	modem_pas: remoteproc-mss@6080000 {
		compatible = "qcom,bengal-modem-pas";
		reg = <0x6080000 0x100>;

		clocks = <&rpmcc RPM_SMD_XO_CLK_SRC>;
		clock-names = "xo";

		cx-supply = <&VDD_CX_LEVEL>;
		cx-uV-uA = <RPMH_REGULATOR_LEVEL_TURBO 100000>;
		reg-names = "cx";

		memory-region = <&pil_modem_mem>;

		/* Inputs from mss */
		interrupts-extended = <&intc 0 307 1>,
				<&modem_smp2p_in 0 0>,
				<&modem_smp2p_in 2 0>,
				<&modem_smp2p_in 1 0>,
				<&modem_smp2p_in 3 0>,
				<&modem_smp2p_in 7 0>;

		interrupt-names = "wdog",
				"fatal",
				"handover",
				"ready",
				"stop-ack",
				"shutdown-ack";

		/* Outputs to mss */
		qcom,smem-states = <&modem_smp2p_out 0>;
		qcom,smem-state-names = "stop";

		glink-edge {
			qcom,remote-pid = <1>;
			transport = "smem";
			mboxes = <&apcs_glb 12>;
			mbox-names = "mpss_smem";
			interrupts = <GIC_SPI 68 IRQ_TYPE_EDGE_RISING>;

			label = "modem";
			qcom,glink-label = "mpss";

			qcom,modem_qrtr {
				qcom,glink-channels = "IPCRTR";
				qcom,intents = <0x800  5
						0x2000 3
						0x4400 2>;
			};

			qcom,msm_fastrpc_rpmsg {
				compatible = "qcom,msm-fastrpc-rpmsg";
				qcom,glink-channels = "fastrpcglink-apps-dsp";
				qcom,intents = <0x64 64>;
			};

			qcom,modem_ds {
				qcom,glink-channels = "DS";
				qcom,intents = <0x4000 2>;
			};
		};
	};

	qcom_pmu: qcom,pmu {
		compatible = "qcom,pmu";
		qcom,pmu-events-tbl =
			< 0x0008 0xFF 0xFF 0xFF >,
			< 0x0011 0xFF 0xFF 0xFF >,
			< 0x0017 0xFF 0xFF 0xFF >;
	};

	ddr_freq_table: ddr-freq-table {
		ddr3 {
			qcom,ddr-type = <5>;
			qcom,freq-tbl =
				<  200000 >,
				<  300000 >,
				<  451000 >,
				<  547000 >,
				<  681000 >,
				<  768000 >,
				<  931000 >;
		};

		ddr4 {
			qcom,ddr-type = <7>;
			qcom,freq-tbl =
				<  200000 >,
				<  547000 >,
				<  768000 >,
				< 1017000 >,
				< 1555000 >,
				< 1804000 >,
				< 2092000 >;
		};
	};

	qcom_dcvs: qcom,dcvs {
		compatible = "qcom,dcvs";
		#address-cells = <1>;
		#size-cells = <1>;
		ranges;

		qcom_ddr_dcvs_hw: ddr {
			compatible = "qcom,dcvs-hw";
			qcom,dcvs-hw-type = <0>;
			qcom,bus-width = <8>;
			qcom,freq-tbl = <&ddr_freq_table>;

			ddr_dcvs_sp: sp {
				compatible = "qcom,dcvs-path";
				qcom,dcvs-path-type = <0>;
				interconnects = <&bimc MASTER_AMPSS_M0 &bimc SLAVE_EBI_CH0>;
			};
		};
	};

	bwmon_ddr: qcom,bwmon-ddr@01b8e200 {
		compatible = "qcom,bwmon4";
		reg = <0x01b8e300 0x100>, <0x01b8e200 0x100>;
		reg-names = "base", "global_base";
		interrupts = <GIC_SPI 421 IRQ_TYPE_LEVEL_HIGH>;
		qcom,mport = <0>;
		qcom,hw-timer-hz = <19200000>;
		qcom,target-dev = <&qcom_ddr_dcvs_hw>;
		qcom,count-unit = <0x10000>;
	};

	qcom_memlat: qcom,memlat {
		compatible = "qcom,memlat";
		ddr {
			compatible = "qcom,memlat-grp";
			qcom,target-dev = <&qcom_ddr_dcvs_hw>;
			qcom,sampling-path = <&ddr_dcvs_sp>;
			qcom,miss-ev = <0x17>;

			silver {
				compatible = "qcom,memlat-mon";
				qcom,cpulist = <&CPU0 &CPU1 &CPU2 &CPU3>;
				qcom,sampling-enabled;
				ddr3-tbl {
					qcom,ddr-type = <5>;
					qcom,cpufreq-memfreq-tbl =
						<  864000 200000 >,
						< 1305600 451000 >,
						< 1804800 768000 >;
				};

				ddr4-tbl {
					qcom,ddr-type = <7>;
					qcom,cpufreq-memfreq-tbl =
						< 1305600  547000 >,
						< 1420000  768000 >,
						< 1904000 1017000 >,
						< 2016000 1555000 >;
				};
			};

			gold {
				compatible = "qcom,memlat-mon";
				qcom,cpulist = <&CPU4 &CPU5 &CPU6 &CPU7>;
				qcom,sampling-enabled;
				ddr3-tbl {
					qcom,ddr-type = <5>;
					qcom,cpufreq-memfreq-tbl =
						< 1056000 200000 >,
						< 1401600 451000 >,
						< 1804800 768000 >,
						< 2016000 931000 >;
				};

				ddr4-tbl {
					qcom,ddr-type = <7>;
					qcom,cpufreq-memfreq-tbl =
						<  902400 547000 >,
						< 1401600 1017000 >,
						< 1804800 1555000 >,
						< 2016000 1804000 >,
						< 2112000 2092000 >;
				};
			};

			silver-compute {
				compatible = "qcom,memlat-mon";
				qcom,cpulist = <&CPU0 &CPU1 &CPU2 &CPU3>;
				qcom,sampling-enabled;
				qcom,compute-mon;
				ddr3-tbl {
					qcom,ddr-type = <5>;
					qcom,cpufreq-memfreq-tbl =
						<  614400 200000 >,
						< 1305600 451000 >,
						< 1804800 768000 >;
				};

				ddr4-tbl {
					qcom,ddr-type = <7>;
					qcom,cpufreq-memfreq-tbl =
						< 1420000  547000 >,
						< 1904000  768000 >,
						< 2016000 1555000 >;
				};
			};

			gold-compute {
				compatible = "qcom,memlat-mon";
				qcom,cpulist = <&CPU4 &CPU5 &CPU6 &CPU7>;
				qcom,sampling-enabled;
				qcom,compute-mon;
				ddr3-tbl {
					qcom,ddr-type = <5>;
					qcom,cpufreq-memfreq-tbl =
						<  652800 200000 >,
						< 1056000 451000 >,
						< 1401600 547000 >,
						< 1536000 768000 >,
						< 2016000 931000 >;
				};

				ddr4-tbl {
					qcom,ddr-type = <7>;
					qcom,cpufreq-memfreq-tbl =
						< 1056000  547000 >,
						< 1401680  768000 >,
						< 1804800 1017000 >,
						< 2016000 1804000 >,
						< 2112000 2092000 >;
				};
			};

		};

	};

	qcom,msm_gsi {
		compatible = "qcom,msm_gsi";
	};

	qcom,rmnet-ipa {
		compatible = "qcom,rmnet-ipa3";
		qcom,rmnet-ipa-ssr;
		qcom,ipa-platform-type-msm;
		qcom,ipa-advertise-sg-support;
		qcom,ipa-napi-enable;
	};

	ipa_hw: qcom,ipa@0x5800000 {
		compatible = "qcom,ipa";
		reg = <0x5800000 0x34000>,
			<0x5804000 0x28000>;
		pas-ids = <0xf>;
		firmware-names = "ipa_fws";
		memory-regions = <&pil_ipa_fw_mem>;
		reg-names = "ipa-base", "gsi-base";
		interrupts = <GIC_SPI 257 IRQ_TYPE_LEVEL_HIGH>,
				<GIC_SPI 259 IRQ_TYPE_LEVEL_HIGH>;
		interrupt-names = "ipa-irq", "gsi-irq";
		qcom,ipa-hw-ver = <16>; /* IPA core version = IPAv4.2 */
		qcom,ipa-hw-mode = <0>;
		qcom,platform-type = <1>; /* MSM platform */
		qcom,ee = <0>;
		qcom,use-ipa-tethering-bridge;
		qcom,modem-cfg-emb-pipe-flt;
		qcom,ipa-wdi2;
		qcom,ipa-wdi2_over_gsi;
		qcom,ipa-endp-delay-wa;
		qcom,ipa-fltrt-not-hashable;
		qcom,use-64-bit-dma-mask;
		qcom,arm-smmu;
		qcom,smmu-fast-map;
		qcom,use-ipa-pm;
		qcom,skip-ieob-mask-wa;
		qcom,max_num_smmu_cb = <3>;
		clocks = <&rpmcc RPM_SMD_IPA_CLK>;
		clock-names = "core_clk";
		qcom,interconnect,num-cases = <5>;
		qcom,interconnect,num-paths = <3>;
		interconnects = <&system_noc MASTER_IPA &bimc SLAVE_EBI_CH0>,
			<&system_noc MASTER_IPA &system_noc SLAVE_OCIMEM>,
			<&bimc MASTER_AMPSS_M0 &config_noc SLAVE_IPA_CFG>;
		interconnect-names = "ipa_to_ebi1", "ipa_to_imem", "appss_to_ipa";
		/* No vote */
		qcom,no-vote =
		<0 0 0 0 0 0>;
		/* SVS2 */
		qcom,svs2 =
		<80000 465000 80000 68570 80000 30>;
		/* SVS */
		qcom,svs =
		<80000 2000000 80000 267461 80000 109890>;
		/* NOMINAL */
		qcom,nominal =
		<206000 4000000 206000 712961 206000 491520>;
		/* TURBO */
		qcom,turbo =
		<206000 5598900 206000 1436481 206000 491520>;
		qcom,bus-vector-names =
				"MIN", "SVS2", "SVS", "NOMINAL", "TURBO";
		qcom,throughput-threshold = <310 600 1000>;
		qcom,scaling-exceptions = <>;

		/* smp2p information */
		qcom,smp2p_map_ipa_1_out {
			compatible = "qcom,smp2p-map-ipa-1-out";
		qcom,smem-states = <&smp2p_ipa_1_out 0>;
			qcom,smem-state-names = "ipa-smp2p-out";
		};

		qcom,smp2p_map_ipa_1_in {
			compatible = "qcom,smp2p-map-ipa-1-in";
			interrupts-extended = <&smp2p_ipa_1_in 0 0>;
			interrupt-names = "ipa-smp2p-in";
		};
	};

	ipa_smmu_ap: ipa_smmu_ap {
		compatible = "qcom,ipa-smmu-ap-cb";
		iommus = <&apps_smmu 0x0140 0x0>;
		qcom,iommu-dma-addr-pool = <0x10000000 0x30000000>;
		/* modem tables in IMEM */
		qcom,iommu-dma = "fastmap";
		qcom,additional-mapping = <0x0c123000 0x0c123000 0x2000>;
		qcom,iommu-geometry = <0 0xB0000000>;
	};

	ipa_smmu_wlan: ipa_smmu_wlan {
		compatible = "qcom,ipa-smmu-wlan-cb";
		iommus = <&apps_smmu 0x0141 0x0>;
		/* ipa-uc ram */
		qcom,iommu-dma = "atomic";
	};

	ipa_smmu_uc: ipa_smmu_uc {
		compatible = "qcom,ipa-smmu-uc-cb";
		iommus = <&apps_smmu 0x0142 0x0>;
		qcom,iommu-dma-addr-pool = <0x40400000 0x1fc00000>;
	};

	qcom,ipa_fws {
		compatible = "qcom,pil-tz-generic";
		qcom,pas-id = <0xf>;
		qcom,firmware-name = "ipa_fws";
		qcom,pil-force-shutdown;
		memory-region = <&pil_ipa_fw_mem>;
		status = "disabled";
	};

	qcom,demux {
		compatible = "qcom,demux";
	};

	msm_gpu: qcom,kgsl-3d0@5900000 { };
};

#include "bengal-gdsc.dtsi"
#include "bengal-usb.dtsi"
#include "khaje-dma-heaps.dtsi"
#include "bengal-coresight.dtsi"
#include "pm6125.dtsi"

&gcc_camss_top_gdsc {
	status = "ok";
};

&gcc_ufs_phy_gdsc {
	status = "ok";
};

&gcc_usb30_prim_gdsc {
	status = "ok";
};

&gcc_vcodec0_gdsc {
	qcom,support-hw-trigger;
	status = "ok";
};

&gcc_venus_gdsc {
	status = "ok";
};

&hlos1_vote_turing_mmu_tbu1_gdsc {
	status = "ok";
};

&hlos1_vote_turing_mmu_tbu0_gdsc {
	status = "ok";
};

&hlos1_vote_mm_snoc_mmu_tbu_rt_gdsc {
	status = "ok";
};

&hlos1_vote_mm_snoc_mmu_tbu_nrt_gdsc {
	status = "ok";
};

&gpu_cx_gdsc {
	parent-supply = <&VDD_CX_LEVEL>;
	status = "ok";
};

&gpu_gx_gdsc {
	parent-supply = <&VDD_CX_LEVEL>;
	status = "ok";
};

#include "msm-arm-smmu-bengal.dtsi"
#include "pm6125-rpm-regulator.dtsi"
#include "bengal-regulator.dtsi"
#include "bengal-pinctrl.dtsi"
#include "bengal-qupv3.dtsi"

&qupv3_se1_i2c {
	status = "ok";
	#include "pm8008.dtsi"
};

&pm8008_8 {
	/* PM8008 IRQ STAT */
	interrupt-parent = <&tlmm>;
	interrupts = <25 IRQ_TYPE_EDGE_RISING>;

	pinctrl-names = "default";
	pinctrl-0 = <&pm8008_active &pm8008_interrupt>;
};

&pm8008_regulators {
	vdd_l1_l2-supply = <&S6A>;
};

&L1P {
	regulator-max-microvolt = <1200000>;
	qcom,min-dropout-voltage = <100000>;
};

&L2P {
	regulator-max-microvolt = <1056000>;
	qcom,min-dropout-voltage = <100000>;
};

&L3P {
	regulator-min-microvolt = <2800000>;
	regulator-max-microvolt = <2800000>;
};

&L4P {
	regulator-min-microvolt = <2800000>;
	regulator-max-microvolt = <2800000>;
};

&L5P {
	regulator-min-microvolt = <2800000>;
	regulator-max-microvolt = <2800000>;
};

&L6P {
	regulator-min-microvolt = <2800000>;
	regulator-max-microvolt = <2800000>;
};

&L7P {
	regulator-min-microvolt = <1800000>;
	regulator-max-microvolt = <1800000>;
};

&qupv3_se4_2uart {
	status = "disable";
};

&qupv3_se3_4uart {
	status = "ok";
};

&pm6125_vadc {
	#address-cells = <1>;
	#size-cells = <0>;
	pinctrl-names = "default";
	pinctrl-0 = <&camera_therm_default &emmc_therm_default>;

	pa_therm0 {
		reg = <ADC5_AMUX_THM1_100K_PU>;
		label = "pa_therm0";
		qcom,ratiometric;
		qcom,hw-settle-time = <200>;
		qcom,pre-scaling = <1 1>;
	};

	quiet_therm {
		reg = <ADC5_AMUX_THM2_100K_PU>;
		label = "quiet_therm";
		qcom,ratiometric;
		qcom,hw-settle-time = <200>;
		qcom,pre-scaling = <1 1>;
	};

	camera_flash_therm {
		reg = <ADC5_GPIO1_100K_PU>;
		label = "camera_flash_therm";
		qcom,ratiometric;
		qcom,hw-settle-time = <200>;
		qcom,pre-scaling = <1 1>;
	};

	emmc_ufs_therm {
		reg = <ADC5_GPIO2_100K_PU>;
		label = "emmc_ufs_therm";
		qcom,ratiometric;
		qcom,hw-settle-time = <200>;
		qcom,pre-scaling = <1 1>;
	};
};

&pm6125_gpios {
	camera_therm {
		camera_therm_default: camera_therm_default {
			pins = "gpio3";
			bias-high-impedance;
		};
	};

	emmc_therm {
		emmc_therm_default: emmc_therm_default {
			pins = "gpio4";
			bias-high-impedance;
		};
	};

};

&spmi_bus {
	qcom,pm6125@0 {
		pm6125_adc_tm_iio: adc_tm@3400 {
			compatible = "qcom,spmi-adc-tm5-iio";
			reg = <0x3400>;
			#thermal-sensor-cells = <1>;
			#address-cells = <1>;
			#size-cells = <0>;

			camera_flash_therm {
				reg = <0>;
				io-channels = <&pm6125_vadc ADC5_GPIO1_100K_PU>;
			};

			emmc_ufs_therm {
				reg = <1>;
				io-channels = <&pm6125_vadc ADC5_GPIO2_100K_PU>;
			};
		};
	};
};

&pm6125_adc_tm {
	#address-cells = <1>;
	#size-cells = <0>;

	/* Channel nodes */
	pa_therm0 {
		reg = <0>;
		io-channels = <&pm6125_vadc ADC5_AMUX_THM1_100K_PU>;
		qcom,ratiometric;
		qcom,hw-settle-time-us = <200>;
	};

	quiet_therm {
		reg = <1>;
		io-channels = <&pm6125_vadc ADC5_AMUX_THM2_100K_PU>;
		qcom,ratiometric;
		qcom,hw-settle-time-us = <200>;
	};

	xo_therm {
		reg = <2>;
		io-channels = <&pm6125_vadc  ADC5_XO_THERM_100K_PU>;
		qcom,ratiometric;
		qcom,hw-settle-time-us = <200>;
	};
};

#include "bengal-thermal.dtsi"
#include "msm-rdbg.dtsi"
